# Template register map
Vendor: VendorName Co.Ltd; Series: SeriesName; File version: 1.2
CPU: CM7 r0p1, little endian, MPU, FPU, 4 interrupt priority bits
Registers are 32-bit, read-write, no defined reset value unless marked. A register's access mark holds for its fields unless they carry their own. Offsets are from the block's base; [hi:lo] are bit positions; {n}, {i} and the like mark numbered series; 'fields as' and 'values as' point back to an identical list.

## EMIF — External Memory Controller
Base 0x400BC000
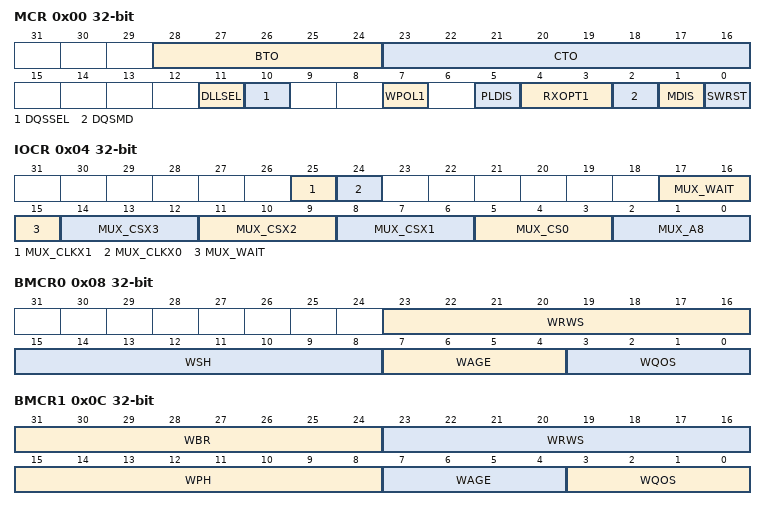
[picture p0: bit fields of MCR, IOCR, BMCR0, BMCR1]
0x00 MCR — EMIF module control register
  [28:24] BTO — EMIF BTO[4:0] bit: bus timeout cycles
  [23:16] CTO — EMIF CTO[7:0] bit: command execution timeout cycles
  [11] DLLSEL — EMIF DLLSEL bit: DLL select
  [10] DQSSEL — EMIF DQSSEL bit: DQS select
  [7] WPOL1 — EMIF WPOL1 bit: R/B polarity for NAND device
  [5] PLDIS — EMIF PLDIS bit: pipeline disable
  [4:3] RXOPT1 — EMIF RXOPT1[1:0] bit: RX option bit 1
  [2] DQSMD — EMIF DQSMD bit: DQS mode
  [1] MDIS — EMIF MDIS bit: module disable
  [0] SWRST — EMIF SWRST bit: software reset
0x04 IOCR — EMIF IO MUX control register
  [25] MUX_CLKX1 — EMIF MUX_CLKX1 bit: SEMC CLKX1 function selection
  [24] MUX_CLKX0 — EMIF MUX_CLKX0 bit: SEMC CLKX0 function selection
  [17:15] MUX_WAIT — EMIF MUX_WAIT[2:0] bit: SEMC WAIT function selection
  [14:12] MUX_CSX3 — EMIF MUX_CSX3[2:0] bit: SEMC CSX3 output selection
  [11:9] MUX_CSX2 — EMIF MUX_CSX2[2:0] bit: SEMC CSX2 output selection
  [8:6] MUX_CSX1 — EMIF MUX_CSX1[2:0] bit: SEMC CSX1 output selection
  [5:3] MUX_CS0 — EMIF MUX_CS0[2:0] bit: SEMC CSX0 output selection
  [2:0] MUX_A8 — EMIF MUX_A8[2:0] bit: SEMC ADDR08 output selection
0x08 BMCR0 — EMIF bus master control register 0
  [23:16] WRWS — EMIF WRWS[7:0] bit: weight of slave hit with read or write switch
  [15:8] WSH — EMIF WSH[7:0] bit: weight of slave hit without read or write switch
  [7:4] WAGE — EMIF WAGE[3:0] bit: weight of AGE
  [3:0] WQOS — EMIF WQOS[3:0] bit: weight of QOS
0x0C BMCR1 — EMIF bus master control register 1
  [31:24] WBR — EMIF WBR[7:0] bit: weight of bank rotation
  [23:16] WRWS — EMIF WRWS[7:0] bit: weight of slave hit without read or write switch
  [15:8] WPH — EMIF WPH[7:0] bit: weight of page hit
  [7:4] WAGE — EMIF WAGE[3:0] bit: weight of AGE
  [3:0] WQOS — EMIF WQOS[3:0] bit: weight of QOS
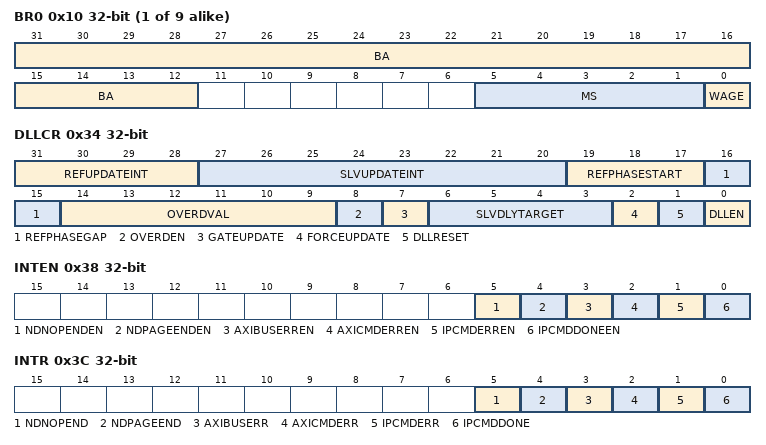
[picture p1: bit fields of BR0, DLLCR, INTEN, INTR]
{0x10+4i} BR{i} (i=0..8) — EMIF base register {i}
  [31:12] BA — EMIF BA[19:0] bit: base address {i}
  [5:1] MS — EMIF MS[4:0] bit: memory size {i}
  [0] WAGE — EMIF WAGE bit: memory whether valid {i}
0x34 DLLCR — EMIF DLL control register
  [31:28] REFUPDATEINT — EMIF REFUPDATEINT[3:0] bit: DLL control loop update interval
  [27:20] SLVUPDATEINT — EMIF SLVUPDATEINT[7:0] bit: update interval from delay line
  [19:17] REFPHASESTART — EMIF REFPHASESTART[2:0] bit: reference clock delay line start phase
  [16:15] REFPHASEGAP — EMIF REFPHASEGAP[1:0] bit: reference clock delay line phase adjustment gap
  [14:9] OVERDVAL — EMIF OVERDVAL[5:0] bit: override value
  [8] OVERDEN — EMIF OVERDEN bit: override enable
  [7] GATEUPDATE — EMIF GATEUPDATE bit: force to close DLL update
  [6:3] SLVDLYTARGET — EMIF SLVDLYTARGET[3:0] bit: delay target for slave
  [2] FORCEUPDATE — EMIF FORCEUPDATE bit: force delay line update to DLL
  [1] DLLRESET — EMIF DLLRESET bit: DLL reset
  [0] DLLEN — EMIF DLLEN bit: DLL calibration enable
0x38 INTEN — EMIF interrupt enable register
  [5] NDNOPENDEN — EMIF NDNOPENDEN bit: NAND no pending AXI access interrupt enable
  [4] NDPAGEENDEN — EMIF NDPAGEENDEN bit: NAND page end interrupt enable
  [3] AXIBUSERREN — EMIF AXIBUSERREN bit: AXI bus error interrupt enable
  [2] AXICMDERREN — EMIF AXICMDERREN bit: AXI command error interrupt enable
  [1] IPCMDERREN — EMIF IPCMDERREN bit: IP command error interrupt enable
  [0] IPCMDDONEEN — EMIF IPCMDDONEEN bit: IP command done interrupt enable
0x3C INTR — EMIF interrupt register
  [5] NDNOPEND — EMIF NDNOPEND bit: NAND no pending AXI write transaction interrupt
  [4] NDPAGEEND — EMIF NDPAGEEND bit: NAND page end interrupt
  [3] AXIBUSERR — EMIF AXIBUSERR bit: AXI bus error interrupt
  [2] AXICMDERR — EMIF AXICMDERR bit: AXI command error interrupt
  [1] IPCMDERR — EMIF IPCMDERR bit: IP command error done interrupt
  [0] IPCMDDONE — EMIF IPCMDDONE bit: IP command normal done interrupt
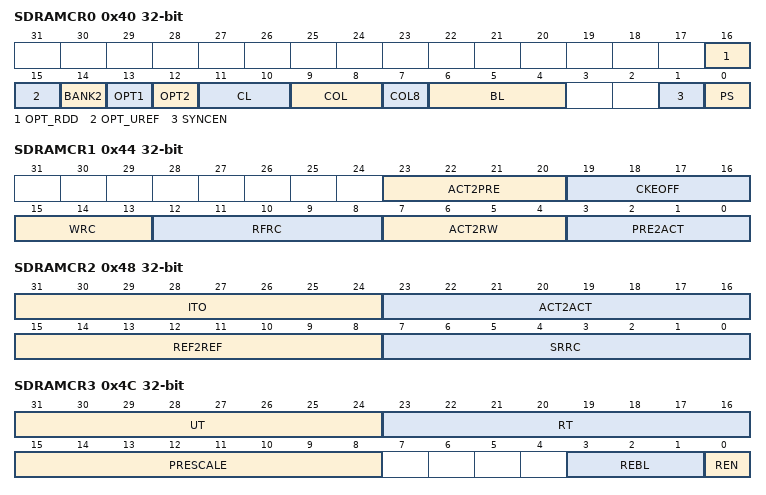
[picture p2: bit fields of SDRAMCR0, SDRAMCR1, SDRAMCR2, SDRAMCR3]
0x40 SDRAMCR0 — EMIF interrupt register
  [16] OPT_RDD — EMIF OPT_RDD bit: desc OPT_RDD
  [15] OPT_UREF — EMIF OPT_UREF bit: desc OPT_UREF
  [14] BANK2 — EMIF BANK2 bit: desc BANK2
  [13] OPT1 — EMIF OPT1 bit: desc OPT1
  [12] OPT2 — EMIF OPT2 bit: desc OPT2
  [11:10] CL — EMIF CL[1:0] bit: desc CL
  [9:8] COL — EMIF COL[1:0] bit: desc COL
  [7] COL8 — EMIF COL8 bit: desc COL8
  [6:4] BL — EMIF BL[2:0] bit: desc BL
  [1] SYNCEN — EMIF SYNCEN bit: desc SYNCEN
  [0] PS — EMIF PS bit: desc PS
0x44 SDRAMCR1 — EMIF SDRAM control register 1
  [23:20] ACT2PRE — EMIF ACT2PRE[3:0] bit: ACTIVE to PRECHARGE minimum time
  [19:16] CKEOFF — EMIF CKEOFF[3:0] bit: CKE off minimum time
  [15:13] WRC — EMIF WRC[2:0] bit: WRITE recovery time
  [12:8] RFRC — EMIF RFRC[4:0] bit: REFRESH recovery time
  [7:4] ACT2RW — EMIF ACT2RW[3:0] bit: ACTIVE to READ or WRITE delay
  [3:0] PRE2ACT — EMIF PRE2ACT[3:0] bit: PRECHARGE to ACTIVE or REFRESH command wait time
0x48 SDRAMCR2 — EMIF SDRAM control register 2
  [31:24] ITO — EMIF ITO[7:0] bit: SDRAM idle timeout
  [23:16] ACT2ACT — EMIF ACT2ACT[7:0] bit: ACTIVE to ACTIVE delay
  [15:8] REF2REF — EMIF REF2REF[7:0] bit: REFRESH to REFRESH delay
  [7:0] SRRC — EMIF SRRC[7:0] bit: SELF REFRESH recovery time
0x4C SDRAMCR3 — EMIF SDRAM control register 3
  [31:24] UT — EMIF UT[7:0] bit: urgent refresh threshold
  [23:16] RT — EMIF RT[7:0] bit: refresh timer period
  [15:8] PRESCALE — EMIF PRESCALE[7:0] bit: prescaler period
  [3:1] REBL — EMIF REBL[2:0] bit: refresh burst length
  [0] REN — EMIF REN bit: refresh enable
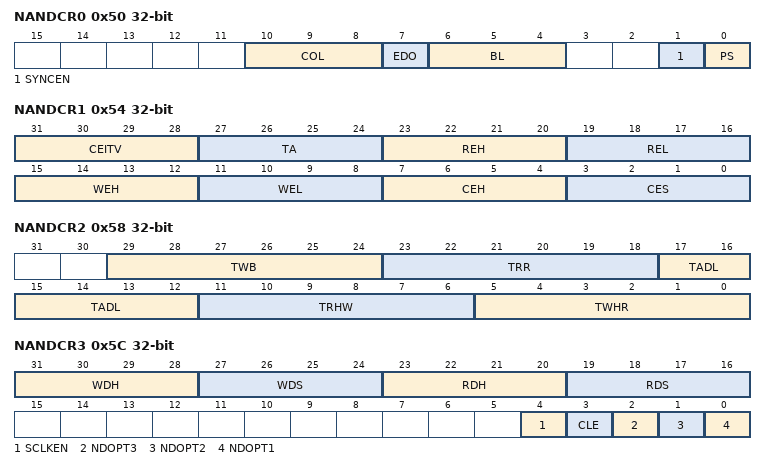
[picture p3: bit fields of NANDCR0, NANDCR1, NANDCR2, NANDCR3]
0x50 NANDCR0 — EMIF NAND control register 0
  [10:8] COL — EMIF COL[2:0] bit: column address bit number
  [7] EDO — EMIF EDO bit: EDO mode enabled
  [6:4] BL — EMIF BL[2:0] bit: burst length
  [1] SYNCEN — EMIF SYNCEN bit: synchronous mode enable
  [0] PS — EMIF PS bit: port size
0x54 NANDCR1 — EMIF NAND control register 1
  [31:28] CEITV — EMIF CEITV[3:0] bit: CE interval time
  [27:24] TA — EMIF TA[3:0] bit: turnaround time
  [23:20] REH — EMIF REH[3:0] bit: RE high time
  [19:16] REL — EMIF REL[3:0] bit: RE low time
  [15:12] WEH — EMIF WEH[3:0] bit: WE high time
  [11:8] WEL — EMIF WEL[3:0] bit: WE low time
  [7:4] CEH — EMIF CEH[3:0] bit: CE hold time
  [3:0] CES — EMIF CES[3:0] bit: CE setup time
0x58 NANDCR2 — EMIF NAND control register 2
  [29:24] TWB — EMIF TWB[5:0] bit: WE high to busy time
  [23:18] TRR — EMIF TRR[5:0] bit: ready to RE low time
  [17:12] TADL — EMIF TADL[5:0] bit: address cycle to data loading time
  [11:6] TRHW — EMIF TRHW[5:0] bit: RE high to WE low time
  [5:0] TWHR — EMIF TWHR[5:0] bit: WE high to RE low time
0x5C NANDCR3 — EMIF NAND control register 3
  [31:28] WDH — EMIF WDH[3:0] bit: write data hold time
  [27:24] WDS — EMIF WDS[3:0] bit: write data setup time
  [23:20] RDH — EMIF RDH[3:0] bit: read data hold time
  [19:16] RDS — EMIF RDS[3:0] bit: read data setup time
  [4] SCLKEN — EMIF SCLKEN bit: synchronous clock enable
  [3] CLE — EMIF CLE bit: NAND CLE option
  [2] NDOPT3 — EMIF NDOPT3 bit: NAND option bit 3
  [1] NDOPT2 — EMIF NDOPT2 bit: NAND option bit 2
  [0] NDOPT1 — EMIF NDOPT1 bit: NAND option bit 1
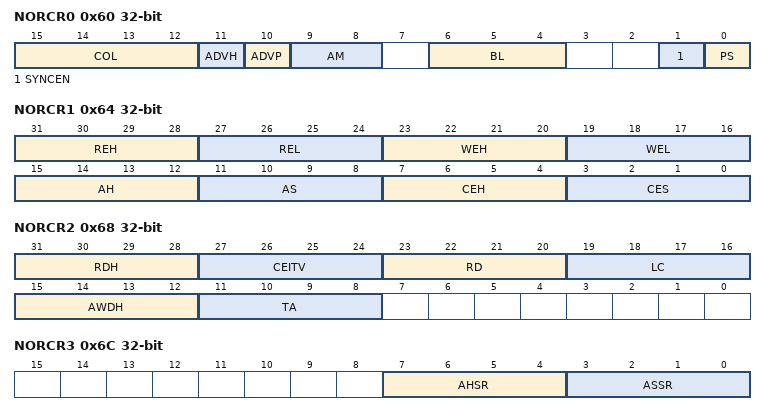
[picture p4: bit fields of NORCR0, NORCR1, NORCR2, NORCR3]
0x60 NORCR0 — EMIF NOR control register 0
  [15:12] COL — EMIF COL[3:0] bit: column address bit width
  [11] ADVH — EMIF ADVH bit: ADV level control during address hold state
  [10] ADVP — EMIF ADVP bit: ADV polarity
  [9:8] AM — EMIF AM[1:0] bit: address mode
  [6:4] BL — EMIF BL[2:0] bit: burst length
  [1] SYNCEN — EMIF SYNCEN bit: synchronous mode enable
  [0] PS — EMIF PS bit: port size
0x64 NORCR1 — EMIF NOR control register 1
  [31:28] REH — EMIF REH[3:0] bit: RE high time
  [27:24] REL — EMIF REL[3:0] bit: RE low time
  [23:20] WEH — EMIF WEH[3:0] bit: WE high time
  [19:16] WEL — EMIF WEL[3:0] bit: WE low time
  [15:12] AH — EMIF AH[3:0] bit: address hold time
  [11:8] AS — EMIF AS[3:0] bit: address setup time
  [7:4] CEH — EMIF CEH[3:0] bit: CE hold time
  [3:0] CES — EMIF CES[3:0] bit: CE setup time
0x68 NORCR2 — EMIF NOR control register 2
  [31:28] RDH — EMIF RDH[3:0] bit: read hold time
  [27:24] CEITV — EMIF CEITV[3:0] bit: CE interval time
  [23:20] RD — EMIF RD[3:0] bit: read time
  [19:16] LC — EMIF LC[3:0] bit: latency count
  [15:12] AWDH — EMIF AWDH[3:0] bit: address to write data hold time
  [11:8] TA — EMIF TA[3:0] bit: turnaround time
0x6C NORCR3 — EMIF NOR control register 3
  [7:4] AHSR — EMIF AHSR[3:0] bit: address hold time for SYNC read
  [3:0] ASSR — EMIF ASSR[3:0] bit: address setup time for SYNC read
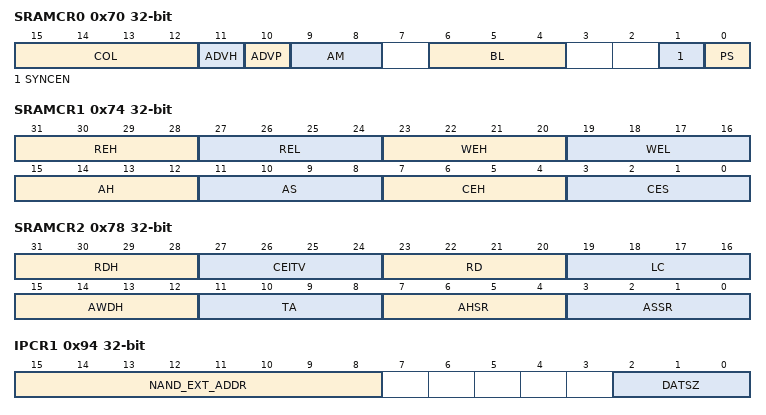
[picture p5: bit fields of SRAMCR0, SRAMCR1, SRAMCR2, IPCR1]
0x70 SRAMCR0 — EMIF SRAM control register 0
  fields as NORCR0
0x74 SRAMCR1 — EMIF SRAM control register 1
  fields as NORCR1
0x78 SRAMCR2 — EMIF SRAM control register 2
  [31:28] RDH — EMIF RDH[3:0] bit: read hold time
  [27:24] CEITV — EMIF CEITV[3:0] bit: CE interval time
  [23:20] RD — EMIF RD[3:0] bit: read time
  [19:16] LC — EMIF LC[3:0] bit: latency count
  [15:12] AWDH — EMIF AWDH[3:0] bit: address to write data hold time
  [11:8] TA — EMIF TA[3:0] bit: turnaround time
  [7:4] AHSR — EMIF AHSR[3:0] bit: write data hold time
  [3:0] ASSR — EMIF ASSR[3:0] bit: write data setup time
0x90 IPCR0 — EMIF IP command control register 0
  [31:0] SA — EMIF SA[31:0] bit: slave address
0x94 IPCR1 — EMIF IP command control register 1
  [15:8] NAND_EXT_ADDR — EMIF NAND_EXT_ADDR[7:0] bit: NAND extended address
  [2:0] DATSZ — EMIF DATSZ[2:0] bit: data size in byte
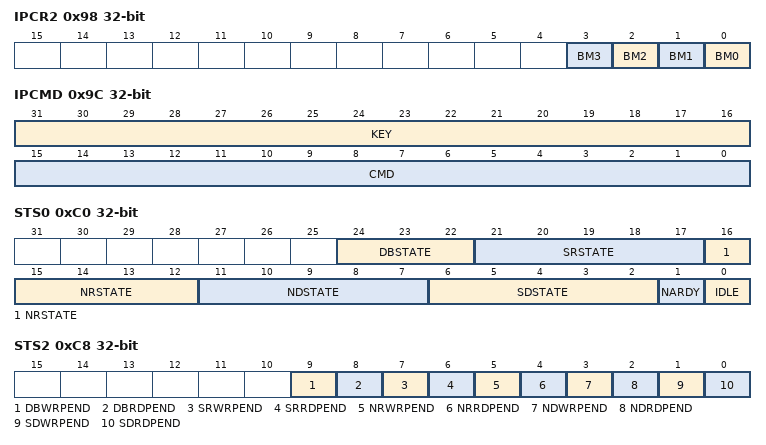
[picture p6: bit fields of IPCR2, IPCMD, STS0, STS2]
0x98 IPCR2 — EMIF IP command control register 2
  [n] BM{n} (n=0..3) — EMIF BM{n} bit: byte mask for byte {n}
0x9C IPCMD — EMIF IP command register
  [31:16] KEY wo — EMIF KEY[15:0] bit: write key bit
  [15:0] CMD — EMIF CMD[15:0] bit: SDRAM commands
0xA0 IPTXDAT — EMIF TX data register
  [31:0] DAT — EMIF DAT[31:0] bit: data value to use for an IP write command
0xB0 IPRXDAT ro — EMIF RX data register
  [31:0] DAT — EMIF DAT[31:0] bit: data returned by device for an IP read command
0xC0 STS0 ro — EMIF status register 0
  [24:22] DBSTATE — EMIF DBSTATE[2:0] bit: DBS controller state
  [21:17] SRSTATE — EMIF SRSTATE[4:0] bit: SRAM controller state
  [16:12] NRSTATE — EMIF NRSTATE[4:0] bit: NOR contorller state
  [11:7] NDSTATE — EMIF NDSTATE[4:0] bit: NAND controller state
  [6:2] SDSTATE — EMIF SDSTATE[4:0] bit: SDRAM controller state
  [1] NARDY — EMIF NARDY bit: indicating NAND device Ready or WAIT pin level
  [0] IDLE — EMIF IDLE bit: indicating whether the SEMC is in idle state
0xC4 STS1 ro — EMIF status register 1
  [31:0] AXIERRCON — EMIF AXIERRCON[31:0] bit: AXI bus error instruct bit
0xC8 STS2 ro — EMIF status register 2
  [9] DBWRPEND — EMIF DBWRPEND bit: whether there is pending AXI command write to DBI device
  [8] DBRDPEND — EMIF DBRDPEND bit: whether there is pending AXI command read to DBI device
  [7] SRWRPEND — EMIF SRWRPEND bit: whether there is pending AXI command write to SRAM device
  [6] SRRDPEND — EMIF SRRDPEND bit: whether there is pending AXI command read to SRAM device
  [5] NRWRPEND — EMIF NRWRPEND bit: whether there is pending AXI command write to NOR device
  [4] NRRDPEND — EMIF NRRDPEND bit: whether there is pending AXI command read to NOR device
  [3] NDWRPEND — EMIF NDWRPEND bit: whether there is pending AXI command write to NAND device
  [2] NDRDPEND — EMIF NDRDPEND bit: whether there is pending AXI command read to NAND device
  [1] SDWRPEND — EMIF SDWRPEND bit: whether there is pending AXI command write to SDRAM device
  [0] SDRDPEND — EMIF SDRDPEND bit: whether there is pending AXI command read to SDRAM device
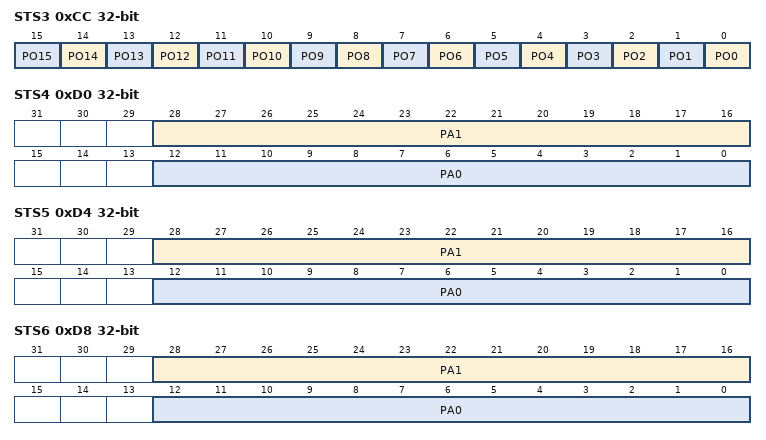
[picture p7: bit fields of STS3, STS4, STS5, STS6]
0xCC STS3 ro — EMIF status register 3
  [n] PO{n} (n=12..15) — EMIF PO{n} bit: whether the instruction page open on SDRAM CS3 Bank{n-12}
  [n] PO{n} (n=8..11) — EMIF PO{n} bit: whether the instruction page open on SDRAM CS2 Bank{n-8}
  [n] PO{n} (n=4..7) — EMIF PO{n} bit: whether the instruction page open on SDRAM CS1 Bank{n-4}
  [n] PO{n} (n=0..3) — EMIF PO{n} bit: whether the instruction page open on SDRAM CS0 Bank{n}
0xD0 STS4 ro — EMIF status register 4
  [28:16] PA1 — EMIF PA1[12:0] bit: instruct the page address opend on SDRAM CS0 or CS2 Bank1
  [12:0] PA0 — EMIF PA0[12:0] bit: instruct the page address opend on SDRAM CS0 or CS2 Bank0
0xD4 STS5 ro — EMIF status register 5
  [28:16] PA1 — EMIF PA1[12:0] bit: instruct the page address opend on SDRAM CS0 or CS2 Bank3
  [12:0] PA0 — EMIF PA0[12:0] bit: instruct the page address opend on SDRAM CS0 or CS2 Bank2
0xD8 STS6 ro — EMIF status register 6
  [28:16] PA1 — EMIF PA1[12:0] bit: instruct the page address opend on SDRAM CS1 or CS3 Bank1
  [12:0] PA0 — EMIF PA0[12:0] bit: instruct the page address opend on SDRAM CS1 or CS3 Bank0
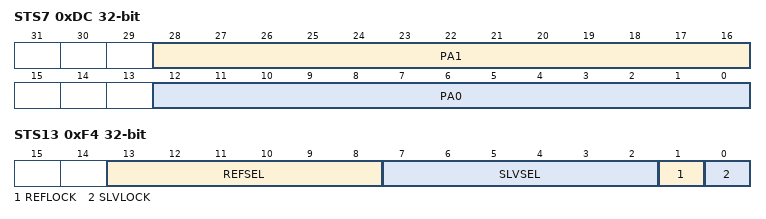
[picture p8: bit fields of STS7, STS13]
0xDC STS7 ro — EMIF status register 7
  [28:16] PA1 — EMIF PA1[12:0] bit: instruct the page address opend on SDRAM CS1 or CS3 Bank3
  [12:0] PA0 — EMIF PA0[12:0] bit: instruct the page address opend on SDRAM CS1 or CS3 Bank2
{0xC0+4i} STS{i} ro (i=8..11) — EMIF status register {i}
  [31:0] AXISTATE{i-8} — EMIF AXISTATE{i-8}[31:0] bit: AXI state {i-8}
0xF0 STS12 ro — EMIF status register 12
  [31:0] NDADDR — EMIF NDADDR[31:0] bit: the last write address to NAND device
0xF4 STS13 ro — EMIF status register 13
  [13:8] REFSEL — EMIF REFSEL[5:0] bit: sample clock reference delay line delay cell number selection
  [7:2] SLVSEL — EMIF SLVSEL[5:0] bit: sample clock slave delay line delay cell number selection
  [1] REFLOCK — EMIF REFLOCK bit: sample clock reference delay line locked
  [0] SLVLOCK — EMIF SLVLOCK bit: sample clock slave delay line locked
